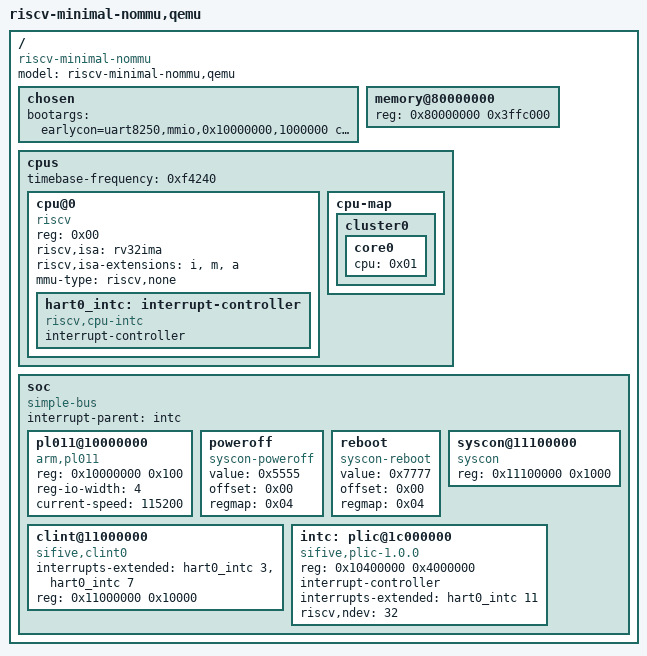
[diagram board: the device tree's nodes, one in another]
/dts-v1/;

/ {
	#address-cells = <0x01>;
	#size-cells = <0x01>;
	compatible = "riscv-minimal-nommu";
	model = "riscv-minimal-nommu,qemu";

	chosen {
		bootargs = "earlycon=uart8250,mmio,0x10000000,1000000 console=ttyS0";
	};

	memory@80000000 {
		device_type = "memory";
		reg = <0x80000000 0x3ffc000>;
	};

	cpus {
		#address-cells = <0x01>;
		#size-cells = <0x00>;
		timebase-frequency = <0xf4240>;

		cpu@0 {
			phandle = <0x01>;
			device_type = "cpu";
			reg = <0x00>;
			status = "okay";
			compatible = "riscv";
			riscv,isa = "rv32ima";
                        riscv,isa-extensions = "i", "m", "a";
			mmu-type = "riscv,none";

			hart0_intc: interrupt-controller {
				#interrupt-cells = <0x01>;
				interrupt-controller;
				compatible = "riscv,cpu-intc";
				phandle = <0x02>;
			};
		};

		cpu-map {

			cluster0 {

				core0 {
					cpu = <0x01>;
				};
			};
		};
	};

  soc {
    interrupt-parent = <&intc>;
    #address-cells = <0x01>;
    #size-cells = <0x01>;
    compatible = "simple-bus";
    ranges;

    pl011@10000000 {
      reg = <0x10000000 0x100>;
      compatible = "arm,pl011", "arm,sbsa-uart";
      reg-io-width = <4>;
      current-speed = <115200>;
    };

    poweroff { // POWER_RESET_SYSCON_POWEROFF
            value = <0x5555>;
            offset = <0x00>;
            regmap = <0x04>;
            compatible = "syscon-poweroff";
    };

    reboot {
            value = <0x7777>;
            offset = <0x00>;
            regmap = <0x04>;
            compatible = "syscon-reboot";
    };

    syscon@11100000 {
            phandle = <0x04>;
            reg = <0x11100000 0x1000>;
            compatible = "syscon";
    };

    clint@11000000 {
            interrupts-extended = <&hart0_intc 3>, <&hart0_intc 7>;
            reg = <0x11000000 0x10000>;
            compatible = "sifive,clint0", "riscv,clint0";
    };
    intc: plic@1c000000 {
      compatible = "sifive,plic-1.0.0";
      reg = <0x10400000 0x4000000>;
      #address-cells = <0>;
      #interrupt-cells = <1>;
      interrupt-controller;
      interrupts-extended = <&hart0_intc 11>;
      // status = "disabled";
      riscv,ndev = <32>;
    };
  };
};
